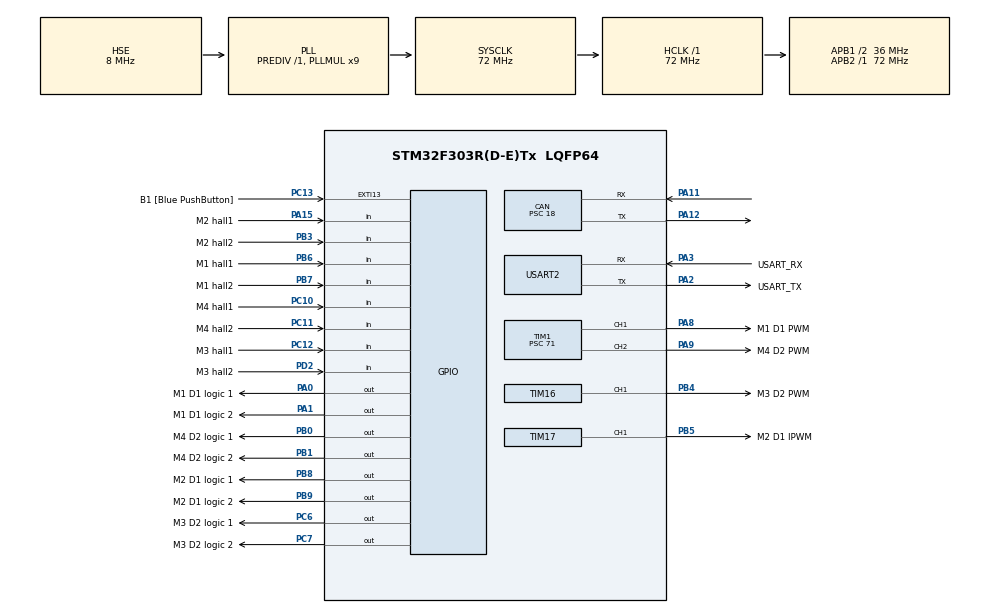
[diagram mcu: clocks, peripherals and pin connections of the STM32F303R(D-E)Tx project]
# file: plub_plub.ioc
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CAN.BS1=CAN_BS1_2TQ
CAN.CalculateBaudRate=500000
CAN.CalculateTimeBit=2000
CAN.CalculateTimeQuantum=500.0
CAN.Prescaler=18
Mcu.Family=STM32F3
Mcu.Name=STM32F303R(D-E)Tx
Mcu.Package=LQFP64
NVIC.PriorityGroup=NVIC_PRIORITYGROUP_0
NVIC.TIM2_IRQn=true\:0\:0\:false\:false\:true\:true\:true\:true
NVIC.USB_LP_CAN_RX0_IRQn=true\:0\:0\:false\:false\:true\:true\:true\:true
PA0.GPIO_Label=M1 D1 logic 1
PA0.Signal=GPIO_Output
PA1.GPIO_Label=M1 D1 logic 2
PA1.Signal=GPIO_Output
PA11.GPIO_PuPd=GPIO_PULLUP
PA11.Mode=CAN_Activate
PA11.Signal=CAN_RX
PA12.GPIO_PuPd=GPIO_NOPULL
PA12.Mode=CAN_Activate
PA12.Signal=CAN_TX
PA13.GPIO_Label=TMS
PA13.Mode=Serial_Wire
PA13.Signal=SYS_JTMS-SWDIO
PA14.GPIO_Label=TCK
PA14.Mode=Serial_Wire
PA14.Signal=SYS_JTCK-SWCLK
PA15.GPIO_Label=M2 hall1
PA15.Signal=GPIO_Input
PA2.GPIO_Label=USART_TX
PA2.GPIO_Mode=GPIO_MODE_AF_PP
PA2.GPIO_PuPd=GPIO_NOPULL
PA2.GPIO_Speed=GPIO_SPEED_FREQ_LOW
PA2.Mode=Asynchronous
PA2.Signal=USART2_TX
PA3.GPIO_Label=USART_RX
PA3.GPIO_Mode=GPIO_MODE_AF_PP
PA3.GPIO_PuPd=GPIO_NOPULL
PA3.GPIO_Speed=GPIO_SPEED_FREQ_LOW
PA3.Mode=Asynchronous
PA3.Signal=USART2_RX
PA8.GPIO_Label=M1 D1 PWM
PA8.Signal=S_TIM1_CH1
PA9.GPIO_Label=M4 D2 PWM
PA9.Signal=S_TIM1_CH2
PB0.GPIO_Label=M4 D2 logic 1
PB0.Signal=GPIO_Output
PB1.GPIO_Label=M4 D2 logic 2
PB1.Signal=GPIO_Output
PB3.GPIO_Label=M2 hall2
PB3.Signal=GPIO_Input
PB4.GPIO_Label=M3 D2 PWM
PB4.Signal=S_TIM16_CH1
PB5.GPIO_Label=M2 D1 lPWM
PB5.Signal=S_TIM17_CH1
PB6.GPIO_Label=M1 hall1
PB6.Signal=GPIO_Input
PB7.GPIO_Label=M1 hall2
PB7.Signal=GPIO_Input
PB8.GPIO_Label=M2 D1 logic 1
PB8.Signal=GPIO_Output
PB9.GPIO_Label=M2 D1 logic 2
PB9.Signal=GPIO_Output
PC10.GPIO_Label=M4 hall1
PC10.Signal=GPIO_Input
PC11.GPIO_Label=M4 hall2
PC11.Signal=GPIO_Input
PC12.GPIO_Label=M3 hall1
PC12.Signal=GPIO_Input
PC13.GPIO_Label=B1 [Blue PushButton]
PC13.GPIO_ModeDefaultEXTI=GPIO_MODE_IT_FALLING
PC13.Signal=GPXTI13
PC14-OSC32_IN.Mode=LSE-External-Oscillator
PC14-OSC32_IN.Signal=RCC_OSC32_IN
PC15-OSC32_OUT.Mode=LSE-External-Oscillator
PC15-OSC32_OUT.Signal=RCC_OSC32_OUT
PC6.GPIO_Label=M3 D2 logic 1
PC6.Signal=GPIO_Output
PC7.GPIO_Label=M3 D2 logic 2
PC7.Signal=GPIO_Output
PD2.GPIO_Label=M3 hall2
PD2.Signal=GPIO_Input
PF0-OSC_IN.Mode=HSE-External-Oscillator
PF0-OSC_IN.Signal=RCC_OSC_IN
PF1-OSC_OUT.Mode=HSE-External-Oscillator
PF1-OSC_OUT.Signal=RCC_OSC_OUT
ProjectManager.HeapSize=0x200
ProjectManager.StackSize=0x400
ProjectManager.TargetToolchain=STM32CubeIDE
RCC.AHBFreq_Value=72000000
RCC.APB1CLKDivider=RCC_HCLK_DIV2
RCC.APB1Freq_Value=36000000
RCC.APB1TimFreq_Value=72000000
RCC.APB2Freq_Value=72000000
RCC.APB2TimCLKDivider=1
RCC.APB2TimFreq_Value=72000000
RCC.CortexFreq_Value=72000000
RCC.HCLKFreq_Value=72000000
RCC.HSE_VALUE=8000000
RCC.HSI_VALUE=8000000
RCC.PLLM=8
RCC.PLLMUL=RCC_PLL_MUL9
RCC.PLLN=336
RCC.PLLP=RCC_PLLP_DIV4
RCC.PLLQ=7
RCC.PLLSourceVirtual=RCC_PLLSOURCE_HSE
RCC.RCC_PLLsource_Clock_Source_FROM_HSE=RCC_HSE_PREDIV_DIV2
RCC.SYSCLKFreq_VALUE=72000000
RCC.SYSCLKSourceVirtual=RCC_SYSCLKSOURCE_PLLCLK
RCC.USBFreq_Value=72000000
SH.S_TIM16_CH1.0=TIM16_CH1,PWM Generation1 CH1
SH.S_TIM17_CH1.0=TIM17_CH1,PWM Generation1 CH1
SH.S_TIM1_CH1.0=TIM1_CH1,PWM Generation1 CH1
SH.S_TIM1_CH2.0=TIM1_CH2,PWM Generation2 CH2
TIM1.AutoReloadPreload=TIM_AUTORELOAD_PRELOAD_ENABLE
TIM1.Channel-PWM\ Generation1\ CH1=TIM_CHANNEL_1
TIM1.Channel-PWM\ Generation2\ CH2=TIM_CHANNEL_2
TIM1.Period=1999
TIM1.Prescaler=71
TIM1.Pulse-PWM\ Generation1\ CH1=0
TIM1.Pulse-PWM\ Generation2\ CH2=0
TIM16.AutoReloadPreload=TIM_AUTORELOAD_PRELOAD_ENABLE
TIM16.Channel=TIM_CHANNEL_1
TIM16.Period=1999
TIM16.Prescaler=71
TIM16.Pulse=0
TIM17.AutoReloadPreload=TIM_AUTORELOAD_PRELOAD_ENABLE
TIM17.Channel=TIM_CHANNEL_1
TIM17.Period=1999
TIM17.Prescaler=71
TIM17.Pulse=0
TIM2.AutoReloadPreload=TIM_AUTORELOAD_PRELOAD_ENABLE
TIM2.Period=9
TIM2.Prescaler=7199
USART2.VirtualMode-Asynchronous=VM_ASYNC
VP_TIM16_VS_ClockSourceINT.Mode=Enable_Timer
VP_TIM17_VS_ClockSourceINT.Mode=Enable_Timer
VP_TIM1_VS_ClockSourceINT.Mode=Internal
VP_TIM2_VS_ClockSourceINT.Mode=Internal
board=NUCLEO-F303RE

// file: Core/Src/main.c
/* USER CODE BEGIN Header */
/**
 ******************************************************************************
 * @file           : main.c
 * @brief          : Main program body
 ******************************************************************************
 * @attention
 *
 * Copyright (c) 2025 STMicroelectronics.
 * All rights reserved.
 *
 * This software is licensed under terms that can be found in the LICENSE file
 * in the root directory of this software component.
 * If no LICENSE file comes with this software, it is provided AS-IS.
 *
 ******************************************************************************
 */
/* USER CODE END Header */
#include "main.h"

/* USER CODE BEGIN Includes */
#include "motor_control.h"
#include "hall_sensor.h"
#include "can.h"
#include <stdbool.h>
#include <stdlib.h>
/* USER CODE END Includes */

CAN_HandleTypeDef hcan;

TIM_HandleTypeDef htim1;
TIM_HandleTypeDef htim2;
TIM_HandleTypeDef htim16;
TIM_HandleTypeDef htim17;

UART_HandleTypeDef huart2;

void SystemClock_Config(void);
static void MX_GPIO_Init(void);
static void MX_USART2_UART_Init(void);
static void MX_TIM17_Init(void);
static void MX_TIM1_Init(void);
static void MX_TIM16_Init(void);
static void MX_CAN_Init(void);
static void MX_TIM2_Init(void);

int main(void)
{

  /* MCU Configuration--------------------------------------------------------*/

  /* Reset of all peripherals, Initializes the Flash interface and the Systick. */
  HAL_Init();

  /* Configure the system clock */
  SystemClock_Config();

  /* Initialize all configured peripherals */
  MX_GPIO_Init();
  MX_USART2_UART_Init();
  MX_TIM17_Init();
  MX_TIM1_Init();
  MX_TIM16_Init();
  MX_CAN_Init();
  MX_TIM2_Init();
  /* USER CODE BEGIN 2 */
	HAL_TIM_PWM_Start(&htim1, TIM_CHANNEL_1);
	HAL_TIM_PWM_Start(&htim1, TIM_CHANNEL_2);
	HAL_TIM_PWM_Start(&htim16, TIM_CHANNEL_1);
	HAL_TIM_PWM_Start(&htim17, TIM_CHANNEL_1);
//	TIM2->CNT = 0;
//	TIM2->SR &= !(1UL);
	HAL_TIM_Base_Start_IT(&htim2);
	init_hall_sensors();

  /* USER CODE END 2 */

  /* Infinite loop */
  /* USER CODE BEGIN WHILE */
	while (1) {
		update_motor_position();
    /* USER CODE END WHILE */

	}
}

void SystemClock_Config(void)
{
  RCC_OscInitTypeDef RCC_OscInitStruct = {0};
  RCC_ClkInitTypeDef RCC_ClkInitStruct = {0};
  RCC_PeriphCLKInitTypeDef PeriphClkInit = {0};

  /** Initializes the RCC Oscillators according to the specified parameters
  * in the RCC_OscInitTypeDef structure.
  */
  RCC_OscInitStruct.OscillatorType = RCC_OSCILLATORTYPE_HSE;
  RCC_OscInitStruct.HSEState = RCC_HSE_ON;
  RCC_OscInitStruct.HSIState = RCC_HSI_ON;
  RCC_OscInitStruct.PLL.PLLState = RCC_PLL_ON;
  RCC_OscInitStruct.PLL.PLLSource = RCC_PLLSOURCE_HSE;
  RCC_OscInitStruct.PLL.PLLMUL = RCC_PLL_MUL9;
  RCC_OscInitStruct.PLL.PREDIV = RCC_PREDIV_DIV1;
  if (HAL_RCC_OscConfig(&RCC_OscInitStruct) != HAL_OK)
  {
    Error_Handler();
  }

  /** Initializes the CPU, AHB and APB buses clocks
  */
  RCC_ClkInitStruct.ClockType = RCC_CLOCKTYPE_HCLK|RCC_CLOCKTYPE_SYSCLK
                              |RCC_CLOCKTYPE_PCLK1|RCC_CLOCKTYPE_PCLK2;
  RCC_ClkInitStruct.SYSCLKSource = RCC_SYSCLKSOURCE_PLLCLK;
  RCC_ClkInitStruct.AHBCLKDivider = RCC_SYSCLK_DIV1;
  RCC_ClkInitStruct.APB1CLKDivider = RCC_HCLK_DIV2;
  RCC_ClkInitStruct.APB2CLKDivider = RCC_HCLK_DIV1;

  if (HAL_RCC_ClockConfig(&RCC_ClkInitStruct, FLASH_LATENCY_2) != HAL_OK)
  {
    Error_Handler();
  }
  PeriphClkInit.PeriphClockSelection = RCC_PERIPHCLK_USART2|RCC_PERIPHCLK_TIM1
                              |RCC_PERIPHCLK_TIM16|RCC_PERIPHCLK_TIM17
                              |RCC_PERIPHCLK_TIM2;
  PeriphClkInit.Usart2ClockSelection = RCC_USART2CLKSOURCE_PCLK1;
  PeriphClkInit.Tim1ClockSelection = RCC_TIM1CLK_HCLK;
  PeriphClkInit.Tim16ClockSelection = RCC_TIM16CLK_HCLK;
  PeriphClkInit.Tim17ClockSelection = RCC_TIM17CLK_HCLK;
  PeriphClkInit.Tim2ClockSelection = RCC_TIM2CLK_HCLK;
  if (HAL_RCCEx_PeriphCLKConfig(&PeriphClkInit) != HAL_OK)
  {
    Error_Handler();
  }
}

static void MX_CAN_Init(void)
{

  hcan.Instance = CAN;
  hcan.Init.Prescaler = 18;
  hcan.Init.Mode = CAN_MODE_NORMAL;
  hcan.Init.SyncJumpWidth = CAN_SJW_1TQ;
  hcan.Init.TimeSeg1 = CAN_BS1_2TQ;
  hcan.Init.TimeSeg2 = CAN_BS2_1TQ;
  hcan.Init.TimeTriggeredMode = DISABLE;
  hcan.Init.AutoBusOff = DISABLE;
  hcan.Init.AutoWakeUp = DISABLE;
  hcan.Init.AutoRetransmission = DISABLE;
  hcan.Init.ReceiveFifoLocked = DISABLE;
  hcan.Init.TransmitFifoPriority = DISABLE;
  if (HAL_CAN_Init(&hcan) != HAL_OK)
  {
    Error_Handler();
  }
  /* USER CODE BEGIN CAN_Init 2 */
	setCanFilter();
  /* USER CODE END CAN_Init 2 */

}

static void MX_TIM1_Init(void)
{

  TIM_ClockConfigTypeDef sClockSourceConfig = {0};
  TIM_MasterConfigTypeDef sMasterConfig = {0};
  TIM_OC_InitTypeDef sConfigOC = {0};
  TIM_BreakDeadTimeConfigTypeDef sBreakDeadTimeConfig = {0};

  htim1.Instance = TIM1;
  htim1.Init.Prescaler = 71;
  htim1.Init.CounterMode = TIM_COUNTERMODE_UP;
  htim1.Init.Period = 1999;
  htim1.Init.ClockDivision = TIM_CLOCKDIVISION_DIV1;
  htim1.Init.RepetitionCounter = 0;
  htim1.Init.AutoReloadPreload = TIM_AUTORELOAD_PRELOAD_ENABLE;
  if (HAL_TIM_Base_Init(&htim1) != HAL_OK)
  {
    Error_Handler();
  }
  sClockSourceConfig.ClockSource = TIM_CLOCKSOURCE_INTERNAL;
  if (HAL_TIM_ConfigClockSource(&htim1, &sClockSourceConfig) != HAL_OK)
  {
    Error_Handler();
  }
  if (HAL_TIM_PWM_Init(&htim1) != HAL_OK)
  {
    Error_Handler();
  }
  sMasterConfig.MasterOutputTrigger = TIM_TRGO_RESET;
  sMasterConfig.MasterOutputTrigger2 = TIM_TRGO2_RESET;
  sMasterConfig.MasterSlaveMode = TIM_MASTERSLAVEMODE_DISABLE;
  if (HAL_TIMEx_MasterConfigSynchronization(&htim1, &sMasterConfig) != HAL_OK)
  {
    Error_Handler();
  }
  sConfigOC.OCMode = TIM_OCMODE_PWM1;
  sConfigOC.Pulse = 0;
  sConfigOC.OCPolarity = TIM_OCPOLARITY_HIGH;
  sConfigOC.OCNPolarity = TIM_OCNPOLARITY_HIGH;
  sConfigOC.OCFastMode = TIM_OCFAST_DISABLE;
  sConfigOC.OCIdleState = TIM_OCIDLESTATE_RESET;
  sConfigOC.OCNIdleState = TIM_OCNIDLESTATE_RESET;
  if (HAL_TIM_PWM_ConfigChannel(&htim1, &sConfigOC, TIM_CHANNEL_1) != HAL_OK)
  {
    Error_Handler();
  }
  if (HAL_TIM_PWM_ConfigChannel(&htim1, &sConfigOC, TIM_CHANNEL_2) != HAL_OK)
  {
    Error_Handler();
  }
  sBreakDeadTimeConfig.OffStateRunMode = TIM_OSSR_DISABLE;
  sBreakDeadTimeConfig.OffStateIDLEMode = TIM_OSSI_DISABLE;
  sBreakDeadTimeConfig.LockLevel = TIM_LOCKLEVEL_OFF;
  sBreakDeadTimeConfig.DeadTime = 0;
  sBreakDeadTimeConfig.BreakState = TIM_BREAK_DISABLE;
  sBreakDeadTimeConfig.BreakPolarity = TIM_BREAKPOLARITY_HIGH;
  sBreakDeadTimeConfig.BreakFilter = 0;
  sBreakDeadTimeConfig.Break2State = TIM_BREAK2_DISABLE;
  sBreakDeadTimeConfig.Break2Polarity = TIM_BREAK2POLARITY_HIGH;
  sBreakDeadTimeConfig.Break2Filter = 0;
  sBreakDeadTimeConfig.AutomaticOutput = TIM_AUTOMATICOUTPUT_DISABLE;
  if (HAL_TIMEx_ConfigBreakDeadTime(&htim1, &sBreakDeadTimeConfig) != HAL_OK)
  {
    Error_Handler();
  }
  HAL_TIM_MspPostInit(&htim1);

}

static void MX_TIM2_Init(void)
{

  TIM_ClockConfigTypeDef sClockSourceConfig = {0};
  TIM_MasterConfigTypeDef sMasterConfig = {0};

  htim2.Instance = TIM2;
  htim2.Init.Prescaler = 7199;
  htim2.Init.CounterMode = TIM_COUNTERMODE_UP;
  htim2.Init.Period = 9;
  htim2.Init.ClockDivision = TIM_CLOCKDIVISION_DIV1;
  htim2.Init.AutoReloadPreload = TIM_AUTORELOAD_PRELOAD_ENABLE;
  if (HAL_TIM_Base_Init(&htim2) != HAL_OK)
  {
    Error_Handler();
  }
  sClockSourceConfig.ClockSource = TIM_CLOCKSOURCE_INTERNAL;
  if (HAL_TIM_ConfigClockSource(&htim2, &sClockSourceConfig) != HAL_OK)
  {
    Error_Handler();
  }
  sMasterConfig.MasterOutputTrigger = TIM_TRGO_RESET;
  sMasterConfig.MasterSlaveMode = TIM_MASTERSLAVEMODE_DISABLE;
  if (HAL_TIMEx_MasterConfigSynchronization(&htim2, &sMasterConfig) != HAL_OK)
  {
    Error_Handler();
  }

}

static void MX_TIM16_Init(void)
{

  TIM_OC_InitTypeDef sConfigOC = {0};
  TIM_BreakDeadTimeConfigTypeDef sBreakDeadTimeConfig = {0};

  htim16.Instance = TIM16;
  htim16.Init.Prescaler = 71;
  htim16.Init.CounterMode = TIM_COUNTERMODE_UP;
  htim16.Init.Period = 1999;
  htim16.Init.ClockDivision = TIM_CLOCKDIVISION_DIV1;
  htim16.Init.RepetitionCounter = 0;
  htim16.Init.AutoReloadPreload = TIM_AUTORELOAD_PRELOAD_ENABLE;
  if (HAL_TIM_Base_Init(&htim16) != HAL_OK)
  {
    Error_Handler();
  }
  if (HAL_TIM_PWM_Init(&htim16) != HAL_OK)
  {
    Error_Handler();
  }
  sConfigOC.OCMode = TIM_OCMODE_PWM1;
  sConfigOC.Pulse = 0;
  sConfigOC.OCPolarity = TIM_OCPOLARITY_HIGH;
  sConfigOC.OCNPolarity = TIM_OCNPOLARITY_HIGH;
  sConfigOC.OCFastMode = TIM_OCFAST_DISABLE;
  sConfigOC.OCIdleState = TIM_OCIDLESTATE_RESET;
  sConfigOC.OCNIdleState = TIM_OCNIDLESTATE_RESET;
  if (HAL_TIM_PWM_ConfigChannel(&htim16, &sConfigOC, TIM_CHANNEL_1) != HAL_OK)
  {
    Error_Handler();
  }
  sBreakDeadTimeConfig.OffStateRunMode = TIM_OSSR_DISABLE;
  sBreakDeadTimeConfig.OffStateIDLEMode = TIM_OSSI_DISABLE;
  sBreakDeadTimeConfig.LockLevel = TIM_LOCKLEVEL_OFF;
  sBreakDeadTimeConfig.DeadTime = 0;
  sBreakDeadTimeConfig.BreakState = TIM_BREAK_DISABLE;
  sBreakDeadTimeConfig.BreakPolarity = TIM_BREAKPOLARITY_HIGH;
  sBreakDeadTimeConfig.BreakFilter = 0;
  sBreakDeadTimeConfig.AutomaticOutput = TIM_AUTOMATICOUTPUT_DISABLE;
  if (HAL_TIMEx_ConfigBreakDeadTime(&htim16, &sBreakDeadTimeConfig) != HAL_OK)
  {
    Error_Handler();
  }
  HAL_TIM_MspPostInit(&htim16);

}

static void MX_TIM17_Init(void)
{

  TIM_OC_InitTypeDef sConfigOC = {0};
  TIM_BreakDeadTimeConfigTypeDef sBreakDeadTimeConfig = {0};

  htim17.Instance = TIM17;
  htim17.Init.Prescaler = 71;
  htim17.Init.CounterMode = TIM_COUNTERMODE_UP;
  htim17.Init.Period = 1999;
  htim17.Init.ClockDivision = TIM_CLOCKDIVISION_DIV1;
  htim17.Init.RepetitionCounter = 0;
  htim17.Init.AutoReloadPreload = TIM_AUTORELOAD_PRELOAD_ENABLE;
  if (HAL_TIM_Base_Init(&htim17) != HAL_OK)
  {
    Error_Handler();
  }
  if (HAL_TIM_PWM_Init(&htim17) != HAL_OK)
  {
    Error_Handler();
  }
  sConfigOC.OCMode = TIM_OCMODE_PWM1;
  sConfigOC.Pulse = 0;
  sConfigOC.OCPolarity = TIM_OCPOLARITY_HIGH;
  sConfigOC.OCNPolarity = TIM_OCNPOLARITY_HIGH;
  sConfigOC.OCFastMode = TIM_OCFAST_DISABLE;
  sConfigOC.OCIdleState = TIM_OCIDLESTATE_RESET;
  sConfigOC.OCNIdleState = TIM_OCNIDLESTATE_RESET;
  if (HAL_TIM_PWM_ConfigChannel(&htim17, &sConfigOC, TIM_CHANNEL_1) != HAL_OK)
  {
    Error_Handler();
  }
  sBreakDeadTimeConfig.OffStateRunMode = TIM_OSSR_DISABLE;
  sBreakDeadTimeConfig.OffStateIDLEMode = TIM_OSSI_DISABLE;
  sBreakDeadTimeConfig.LockLevel = TIM_LOCKLEVEL_OFF;
  sBreakDeadTimeConfig.DeadTime = 0;
  sBreakDeadTimeConfig.BreakState = TIM_BREAK_DISABLE;
  sBreakDeadTimeConfig.BreakPolarity = TIM_BREAKPOLARITY_HIGH;
  sBreakDeadTimeConfig.BreakFilter = 0;
  sBreakDeadTimeConfig.AutomaticOutput = TIM_AUTOMATICOUTPUT_DISABLE;
  if (HAL_TIMEx_ConfigBreakDeadTime(&htim17, &sBreakDeadTimeConfig) != HAL_OK)
  {
    Error_Handler();
  }
  HAL_TIM_MspPostInit(&htim17);

}

static void MX_USART2_UART_Init(void)
{

  huart2.Instance = USART2;
  huart2.Init.BaudRate = 38400;
  huart2.Init.WordLength = UART_WORDLENGTH_8B;
  huart2.Init.StopBits = UART_STOPBITS_1;
  huart2.Init.Parity = UART_PARITY_NONE;
  huart2.Init.Mode = UART_MODE_TX_RX;
  huart2.Init.HwFlowCtl = UART_HWCONTROL_NONE;
  huart2.Init.OverSampling = UART_OVERSAMPLING_16;
  huart2.Init.OneBitSampling = UART_ONE_BIT_SAMPLE_DISABLE;
  huart2.AdvancedInit.AdvFeatureInit = UART_ADVFEATURE_NO_INIT;
  if (HAL_UART_Init(&huart2) != HAL_OK)
  {
    Error_Handler();
  }

}

static void MX_GPIO_Init(void)
{
  GPIO_InitTypeDef GPIO_InitStruct = {0};

  /* GPIO Ports Clock Enable */
  __HAL_RCC_GPIOC_CLK_ENABLE();
  __HAL_RCC_GPIOF_CLK_ENABLE();
  __HAL_RCC_GPIOA_CLK_ENABLE();
  __HAL_RCC_GPIOB_CLK_ENABLE();
  __HAL_RCC_GPIOD_CLK_ENABLE();

  /*Configure GPIO pin Output Level */
  HAL_GPIO_WritePin(GPIOA, M1_D1_logic_1_Pin|M1_D1_logic_2_Pin, GPIO_PIN_RESET);

  /*Configure GPIO pin Output Level */
  HAL_GPIO_WritePin(GPIOB, M4_D2_logic_1_Pin|M4_D2_logic_2_Pin|M2_D1_logic_1_Pin|M2_D1_logic_2_Pin, GPIO_PIN_RESET);

  /*Configure GPIO pin Output Level */
  HAL_GPIO_WritePin(GPIOC, M3_D2_logic_1_Pin|M3_D2_logic_2_Pin, GPIO_PIN_RESET);

  /*Configure GPIO pin : B1_Pin */
  GPIO_InitStruct.Pin = B1_Pin;
  GPIO_InitStruct.Mode = GPIO_MODE_IT_FALLING;
  GPIO_InitStruct.Pull = GPIO_NOPULL;
  HAL_GPIO_Init(B1_GPIO_Port, &GPIO_InitStruct);

  /*Configure GPIO pins : M1_D1_logic_1_Pin M1_D1_logic_2_Pin */
  GPIO_InitStruct.Pin = M1_D1_logic_1_Pin|M1_D1_logic_2_Pin;
  GPIO_InitStruct.Mode = GPIO_MODE_OUTPUT_PP;
  GPIO_InitStruct.Pull = GPIO_NOPULL;
  GPIO_InitStruct.Speed = GPIO_SPEED_FREQ_LOW;
  HAL_GPIO_Init(GPIOA, &GPIO_InitStruct);

  /*Configure GPIO pins : M4_D2_logic_1_Pin M4_D2_logic_2_Pin M2_D1_logic_1_Pin M2_D1_logic_2_Pin */
  GPIO_InitStruct.Pin = M4_D2_logic_1_Pin|M4_D2_logic_2_Pin|M2_D1_logic_1_Pin|M2_D1_logic_2_Pin;
  GPIO_InitStruct.Mode = GPIO_MODE_OUTPUT_PP;
  GPIO_InitStruct.Pull = GPIO_NOPULL;
  GPIO_InitStruct.Speed = GPIO_SPEED_FREQ_LOW;
  HAL_GPIO_Init(GPIOB, &GPIO_InitStruct);

  /*Configure GPIO pins : M3_D2_logic_1_Pin M3_D2_logic_2_Pin */
  GPIO_InitStruct.Pin = M3_D2_logic_1_Pin|M3_D2_logic_2_Pin;
  GPIO_InitStruct.Mode = GPIO_MODE_OUTPUT_PP;
  GPIO_InitStruct.Pull = GPIO_NOPULL;
  GPIO_InitStruct.Speed = GPIO_SPEED_FREQ_LOW;
  HAL_GPIO_Init(GPIOC, &GPIO_InitStruct);

  /*Configure GPIO pin : M2_hall1_Pin */
  GPIO_InitStruct.Pin = M2_hall1_Pin;
  GPIO_InitStruct.Mode = GPIO_MODE_INPUT;
  GPIO_InitStruct.Pull = GPIO_NOPULL;
  HAL_GPIO_Init(M2_hall1_GPIO_Port, &GPIO_InitStruct);

  /*Configure GPIO pins : M4_hall1_Pin M4_hall2_Pin M3_hall1_Pin */
  GPIO_InitStruct.Pin = M4_hall1_Pin|M4_hall2_Pin|M3_hall1_Pin;
  GPIO_InitStruct.Mode = GPIO_MODE_INPUT;
  GPIO_InitStruct.Pull = GPIO_NOPULL;
  HAL_GPIO_Init(GPIOC, &GPIO_InitStruct);

  /*Configure GPIO pin : M3_hall2_Pin */
  GPIO_InitStruct.Pin = M3_hall2_Pin;
  GPIO_InitStruct.Mode = GPIO_MODE_INPUT;
  GPIO_InitStruct.Pull = GPIO_NOPULL;
  HAL_GPIO_Init(M3_hall2_GPIO_Port, &GPIO_InitStruct);

  /*Configure GPIO pins : M2_hall2_Pin M1_hall1_Pin M1_hall2_Pin */
  GPIO_InitStruct.Pin = M2_hall2_Pin|M1_hall1_Pin|M1_hall2_Pin;
  GPIO_InitStruct.Mode = GPIO_MODE_INPUT;
  GPIO_InitStruct.Pull = GPIO_NOPULL;
  HAL_GPIO_Init(GPIOB, &GPIO_InitStruct);

}

void Error_Handler(void)
{
	__disable_irq();
	while (1) {
	}
}
